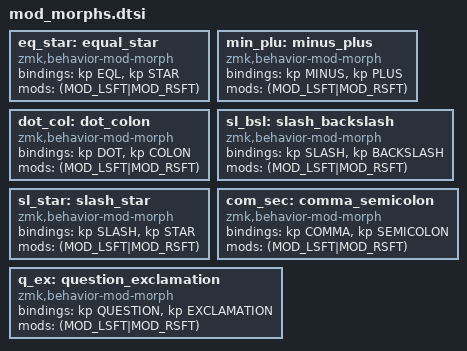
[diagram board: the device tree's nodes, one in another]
eq_star: equal_star {
    compatible = "zmk,behavior-mod-morph";
    #binding-cells = <0>;
    bindings = <&kp EQL>, <&kp STAR>;
    mods = <(MOD_LSFT|MOD_RSFT)>;
    // keep-mods = <(MOD_LSFT|MOD_RSFT)>;
};

min_plu: minus_plus {
    compatible = "zmk,behavior-mod-morph";
    #binding-cells = <0>;
    bindings = <&kp MINUS>, <&kp PLUS>;
    mods = <(MOD_LSFT|MOD_RSFT)>;
    // keep-mods = <(MOD_LSFT|MOD_RSFT)>;
};

dot_col: dot_colon {
    compatible = "zmk,behavior-mod-morph";
    #binding-cells = <0>;
    bindings = <&kp DOT>, <&kp COLON>;
    mods = <(MOD_LSFT|MOD_RSFT)>;
    // keep-mods = <(MOD_LSFT|MOD_RSFT)>;
};

sl_bsl: slash_backslash {
    compatible = "zmk,behavior-mod-morph";
    #binding-cells = <0>;
    bindings = <&kp SLASH>, <&kp BACKSLASH>;
    mods = <(MOD_LSFT|MOD_RSFT)>;
};

sl_star: slash_star {
    compatible = "zmk,behavior-mod-morph";
    #binding-cells = <0>;
    bindings = <&kp SLASH>, <&kp STAR>;
    mods = <(MOD_LSFT|MOD_RSFT)>;
};

com_sec: comma_semicolon {
    compatible = "zmk,behavior-mod-morph";
    #binding-cells = <0>;
    bindings = <&kp COMMA>, <&kp SEMICOLON>;
    mods = <(MOD_LSFT|MOD_RSFT)>;
};

q_ex: question_exclamation {
    compatible = "zmk,behavior-mod-morph";
    #binding-cells = <0>;
    bindings = <&kp QUESTION>, <&kp EXCLAMATION >;
    mods = <(MOD_LSFT|MOD_RSFT)>;
    // keep-mods = <(MOD_LSFT|MOD_RSFT)>;
};
